# MSS_CTRL_MSS_CTRL_50D00000h register map
Vendor: Texas Instruments
Registers are 32-bit, read-only, reset values left out (the file's numbers can be read two ways) unless marked. A register's access mark holds for its fields unless they carry their own. Offsets are as the file gives them; [hi:lo] are bit positions; {n}, {i} and the like mark numbered series.

## MSS_CTRL (part 2 of 10)
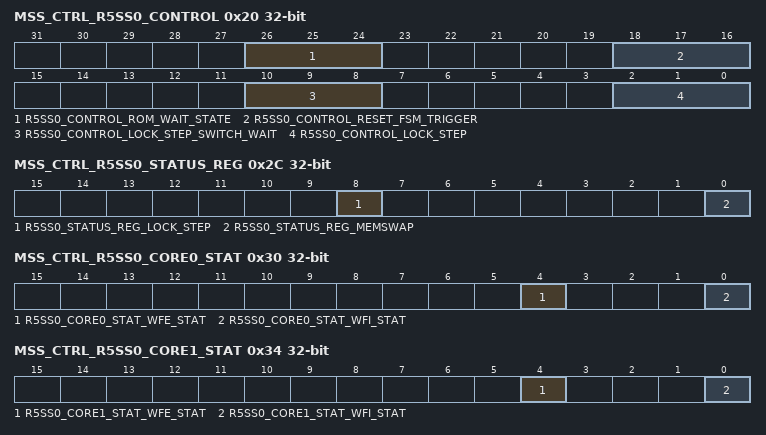
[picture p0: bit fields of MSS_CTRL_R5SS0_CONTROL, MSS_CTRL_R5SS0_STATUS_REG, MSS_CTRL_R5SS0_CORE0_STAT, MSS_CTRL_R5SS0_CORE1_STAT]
0x20 MSS_CTRL_R5SS0_CONTROL rw — This register is used to configure R5SS0 in Lock step or Dual core mode. The mode change can be affected only once in a SOC power cycle.
  [26:24] R5SS0_CONTROL_ROM_WAIT_STATE — Writing 3'b111 enables a single cycle wait state with respect to CR5A_clk for rom access.This needs to be set when R5 clock is at 400MHZ and Interconnect-clk is at 200MHZ. [because it is a timing issue in this scenario]
  [18:16] R5SS0_CONTROL_RESET_FSM_TRIGGER — Write pulse bit field:Writing 3'b111 will trigger the reset FSM. Reset FSM ensures reset to R5SS and inturn ensures the latching of lock_step and also mem_swap bit
  [10:8] R5SS0_CONTROL_LOCK_STEP_SWITCH_WAIT — Writing 3'b111 ensures switch happens only after R5SS reset. Orelse it will be a immediate switch.
  [2:0] R5SS0_CONTROL_LOCK_STEP — Writing 3'b000 ensures R5 to be in Dual-Core mode. Note: The change happens after the R5SS reset assertion if corresponding R5SS_CONTROL_LOCK_STEP_SWITCH_WAIT is set. Or else the switiching to Dual-core happens on the fly.
0x24 MSS_CTRL_R5SS0_CORE0_HALT rw — This register is used to Halt or Unhalt R5SS0 Core 0
  [2:0] R5SS0_COREA_HALT_HALT — Writing 3'b000 will unhalt CR5A. This register should be written only once.
0x28 MSS_CTRL_R5SS0_CORE1_HALT rw — This register is used to Halt or Unhalt R5SS0 Core 1
  [2:0] R5SS0_COREB_HALT_HALT — Writing 3'b000 will unhalt for CR5B. This register should be written only once.
0x2C MSS_CTRL_R5SS0_STATUS_REG — This register shows whether R5SS0 is in Lock step or Dual core mode.
  [8] R5SS0_STATUS_REG_LOCK_STEP — Reading1:confirms R5SS is in lockstep mode. Reading0:confirms R5SS is in Dual-core mode.
  [0] R5SS0_STATUS_REG_MEMSWAP — Reading1:confirms ROM is Eclipsed from with RAM for R5.
0x30 MSS_CTRL_R5SS0_CORE0_STAT — This register shows the WFI WFE status of R5SS0 Core 0
  [4] R5SS0_CORE0_STAT_WFE_STAT — WFE Status
  [0] R5SS0_CORE0_STAT_WFI_STAT — WFI Status
0x34 MSS_CTRL_R5SS0_CORE1_STAT — This register shows the WFI WFE status of R5SS0 Core 1
  [4] R5SS0_CORE1_STAT_WFE_STAT — WFE Status
  [0] R5SS0_CORE1_STAT_WFI_STAT — WFI Status
0x38 MSS_CTRL_MSS_STC_CONTROL0 rw — This register is used to override and force WFI from R5SS0 to RCM.
  [2:0] MSS_STC_CONTROL0_CR5_WFI_OVERIDE — Writing 3'b111 will force the wfi signals of R5SS to 1
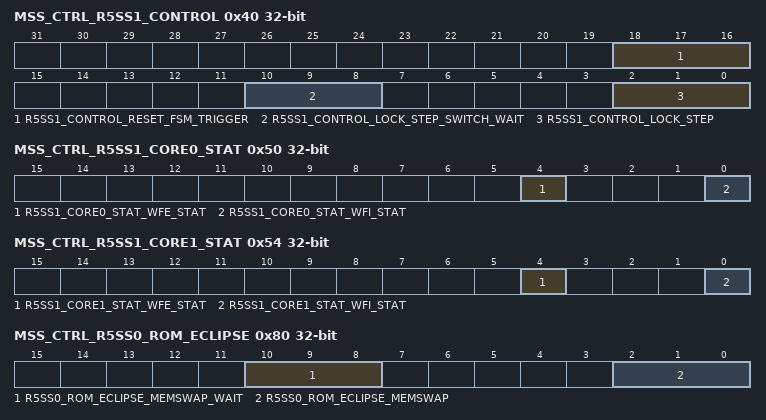
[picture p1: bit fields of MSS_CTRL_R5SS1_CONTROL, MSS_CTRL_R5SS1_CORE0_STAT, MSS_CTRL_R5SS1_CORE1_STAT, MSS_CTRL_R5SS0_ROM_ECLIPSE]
0x40 MSS_CTRL_R5SS1_CONTROL rw — This register is used to configure corresponding R5SS in Lock step or Dual core mode. The mode change can be affected only once in a SOC power cycle.
  [18:16] R5SS1_CONTROL_RESET_FSM_TRIGGER — Write pulse bit field:Writing 3'b111 will trigger the reset FSM. Reset FSM ensures reset to R5SS and inturn ensures the latching of lock_step and also mem_swap bit
  [10:8] R5SS1_CONTROL_LOCK_STEP_SWITCH_WAIT — Writing 3'b111 ensures switch happens only after R5SS reset. Orelse it will be a immediate switch.
  [2:0] R5SS1_CONTROL_LOCK_STEP — Writing 3'b000 ensures R5 to be in Dual-Core mode. Note: The change happens after the R5SS reset assertion if corresponding R5SS_CONTROL_LOCK_STEP_SWITCH_WAIT is set. Or else the switiching to Dual-core happens on the fly.
0x44 MSS_CTRL_R5SS1_CORE0_HALT rw — This register is used to Halt or Unhalt R5SS1 Core 0
  [2:0] R5SS1_COREA_HALT_HALT — Writing 3'b000 will unhalt CR5A. This register should be written only once.
0x48 MSS_CTRL_R5SS1_CORE1_HALT rw — This register is used to Halt or Unhalt R5SS1 Core 1
  [2:0] R5SS1_COREB_HALT_HALT — Writing 3'b000 will unhalt for CR5B. This register should be written only once.
0x4C MSS_CTRL_R5SS1_STATUS_REG — This register shows whether R5SS1 is in Lock step or Dual core mode.
  [8] R5SS1_STATUS_REG_LOCK_STEP — Reading1:confirms R5SS is in lockstep mode. Reading0:confirms R5SS is in Dual-core mode.
0x50 MSS_CTRL_R5SS1_CORE0_STAT — This register shows the WFI WFE status of R5SS1 Core 0
  [4] R5SS1_CORE0_STAT_WFE_STAT — WFE Status
  [0] R5SS1_CORE0_STAT_WFI_STAT — WFI Status
0x54 MSS_CTRL_R5SS1_CORE1_STAT — This register shows the WFI WFE status of R5SS1 Core 1
  [4] R5SS1_CORE1_STAT_WFE_STAT — WFE Status
  [0] R5SS1_CORE1_STAT_WFI_STAT — WFI Status
0x58 MSS_CTRL_MSS_STC_CONTROL1 rw — This register is used to override and force WFI from R5SS1 to RCM.
  [2:0] MSS_STC_CONTROL1_CR5_WFI_OVERIDE — Writing 3'b111 will force the wfi signals of R5SS to 1
0x80 MSS_CTRL_R5SS0_ROM_ECLIPSE rw — R5_ROM_ECLIPSE.
  [10:8] R5SS0_ROM_ECLIPSE_MEMSWAP_WAIT — Writing 3'b111 ensures ROM-Eclipsing happens only after R5SS reset. Or else it will be a immediate change.
  [2:0] R5SS0_ROM_ECLIPSE_MEMSWAP — Writing 3'b111 ensures eclipsing of CR5A_ROM immediately if memswap_wait is not set. If memswap_wait is set then ROM is eclipsed after R5SS reset assertion.
{0x100+4i} MSS_CTRL_MSS_BOOT_INFO_REG{i} rw (i=0..7) — MSS_BOOT_INFO_REG{i}.
  [31:0] MSS_BOOT_INFO_REG{i}_CONFIG — Reserved Register for Software use**Note: Bit is getting reseted only on PORz
0x200 MSS_CTRL_MSS_ATCM0_MEM_INIT rw — This register is used to initialise the data and ECC of ATCM memory of R5SS0 .
  [0] MSS_ATCM0_MEM_INIT_MEM_INIT — Write_pulse bit field:Writing 1'b1 will start initializing the ATCM banks of CR5A/B. Value in each row is initialized to 0x0C_0000_0000
0x204 MSS_CTRL_MSS_ATCM0_MEM_INIT_DONE rw — This register is used to indicate the ATCM memory initialization completion for R5SS0.
  [0] MSS_ATCM0_MEM_INIT_DONE_MEM_INIT_DONE — This field will be high once initialization of ATCM banks is finished. Writing '1' would clear the bit.
0x208 MSS_CTRL_MSS_ATCM0_MEM_INIT_STATUS — This register is used to indicate the status of ongoing memory initialization for ATCM memory of R5SS0.
  [0] MSS_ATCM0_MEM_INIT_STATUS_MEM_STATUS — 1'b0: No initialization is happening for ATCM banks of CR5A/B1'b1: Initialization is in progress for ATCM banks of CR5A/B
0x210 MSS_CTRL_MSS_BTCM0_MEM_INIT rw — This register is used to initialise the data and ECC of BTCM memory of R5SS0 .
  [0] MSS_BTCM0_MEM_INIT_MEM_INIT — Write_pulse bit field:Writing 1'b1 will start initializing the B0/1TCM banks of CR5A/B
0x214 MSS_CTRL_MSS_BTCM0_MEM_INIT_DONE rw — This register is used to indicate the BTCM memory initialization completion for R5SS0.
  [0] MSS_BTCM0_MEM_INIT_DONE_MEM_INIT_DONE — This field will be high once initialization of B0/1TCM banks is finished. Writing '1' would clear the bit.
0x218 MSS_CTRL_MSS_BTCM0_MEM_INIT_STATUS — This register is used to indicate the status of ongoing memory initialization for BTCM memory of R5SS0.
  [0] MSS_BTCM0_MEM_INIT_STATUS_MEM_STATUS — 1'b0: No initialization is happening for B0/1TCM banks of CR5A/B1'b1: Initialization is in progress for B0/1TCM banks of CR5A/B
0x220 MSS_CTRL_MSS_ATCM1_MEM_INIT rw — This register is used to initialise the data and ECC of ATCM memory of R5SS1.
  [0] MSS_ATCM1_MEM_INIT_MEM_INIT — Write_pulse bit field:Writing 1'b1 will start initializing the ATCM banks of CR5A/B. Value in each row is initialized to 0x0C_0000_0000
0x224 MSS_CTRL_MSS_ATCM1_MEM_INIT_DONE rw — This register is used to indicate the ATCM memory initialization completion for R5SS1.
  [0] MSS_ATCM1_MEM_INIT_DONE_MEM_INIT_DONE — This field will be high once initialization of ATCM banks is finished. Writing '1' would clear the bit.
0x228 MSS_CTRL_MSS_ATCM1_MEM_INIT_STATUS — This register is used to indicate the status of ongoing memory initialization for ATCM memory of R5SS1.
  [0] MSS_ATCM1_MEM_INIT_STATUS_MEM_STATUS — 1'b0: No initialization is happening for ATCM banks of CR5A/B1'b1: Initialization is in progress for ATCM banks of CR5A/B
0x230 MSS_CTRL_MSS_BTCM1_MEM_INIT rw — This register is used to initialise the data and ECC of BTCM memory of R5SS1.
  [0] MSS_BTCM1_MEM_INIT_MEM_INIT — Write_pulse bit field:Writing 1'b1 will start initializing the B0/1TCM banks of CR5A/B
0x234 MSS_CTRL_MSS_BTCM1_MEM_INIT_DONE rw — This register is used to indicate the BTCM memory initialization completion for R5SS1.
  [0] MSS_BTCM1_MEM_INIT_DONE_MEM_INIT_DONE — This field will be high once initialization of B0/1TCM banks is finished. Writing '1' would clear the bit.
0x238 MSS_CTRL_MSS_BTCM1_MEM_INIT_STATUS — This register is used to indicate the status of ongoing memory initialization for BTCM memory of R5SS1.
  [0] MSS_BTCM1_MEM_INIT_STATUS_MEM_STATUS — 1'b0: No initialization is happening for B0/1TCM banks of CR5A/B1'b1: Initialization is in progress for B0/1TCM banks of CR5A/B
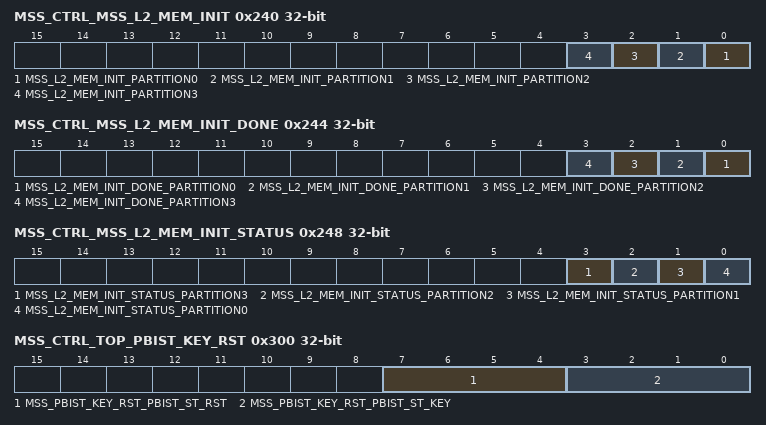
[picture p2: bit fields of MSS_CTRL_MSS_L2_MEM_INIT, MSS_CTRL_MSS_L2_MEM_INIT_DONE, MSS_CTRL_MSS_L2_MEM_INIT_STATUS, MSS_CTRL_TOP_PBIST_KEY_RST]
0x240 MSS_CTRL_MSS_L2_MEM_INIT rw — This register is used to initialise the data and ECC of L2OCRAM.
  [n] MSS_L2_MEM_INIT_PARTITION{n} (n=0..3) — Write_pulse bit field:Writing 1'b1 will start initializing the L2 Bank{n}. Value in each row is initialized to 0x0
0x244 MSS_CTRL_MSS_L2_MEM_INIT_DONE rw — This register is used to indicate the L2OCRAM memory initialization completion .
  [n] MSS_L2_MEM_INIT_DONE_PARTITION{n} (n=0..3) — This field will be high once intialization of L2 bank{n} is finished. Writing '1' would clear the bit
0x248 MSS_CTRL_MSS_L2_MEM_INIT_STATUS — This register is used to indicate the status of ongoing memory initialization for L2OCRAM.
  [3] MSS_L2_MEM_INIT_STATUS_PARTITION3 — 1'b0: No initialization is happening for L2 bank31'b1: Initialization is in progress for L2 bank3
  [2] MSS_L2_MEM_INIT_STATUS_PARTITION2 — 1'b0: No initialization is happening for L2 bank2 1'b1: Initialization is in progress for L2 bank2
  [1] MSS_L2_MEM_INIT_STATUS_PARTITION1 — 1'b0: No initialization is happening for L2 bank11'b1: Initialization is in progress for L2 bank1
  [0] MSS_L2_MEM_INIT_STATUS_PARTITION0 — 1'b0: No initialization is happening for L2 bank0 1'b1: Initialization is in progress for L2 bank0
0x250 MSS_CTRL_MSS_MAILBOX_MEM_INIT rw — This register is used to initialise the data and ECC of MBOX_SRAM.
  [0] MSS_MAILBOX_MEM_INIT_MEM0_INIT — Write_pulse bit field:Writing 1'b1 will start initializing the MSS_MBOX. Value in each row is initialized to 0x0
0x254 MSS_CTRL_MSS_MAILBOX_MEM_INIT_DONE rw — This register is used to indicate the MBOX_SRAM memory initialization completion .
  [0] MSS_MAILBOX_MEM_INIT_DONE_MEM0_DONE — This field will be high once intialization of MSS_MBOX is finished. Writing '1' would clear the bit
0x258 MSS_CTRL_MSS_MAILBOX_MEM_INIT_STATUS — This register is used to indicate the status of ongoing memory initialization for MBOX_SRAM.
  [0] MSS_MAILBOX_MEM_INIT_STATUS_MEM0_STATUS — 1'b0: No initialization is happening for MSS_MBOX 1'b1: Initialization is in progress for MSS_MBOX
0x260 MSS_CTRL_MSS_TPCC_MEMINIT_START rw — This register is used to initialise the data and ECC of EDMA_TPCC RAM.
  [0] MSS_TPCC_MEMINIT_START_TPCC_A_MEMINIT_START — Write_pulse bit field:Writing 1'b1 will start initializing the MSS_TPCCA
0x264 MSS_CTRL_MSS_TPCC_MEMINIT_DONE rw — This register is used to indicate the EDMA_TPCC memory initialization completion .
  [0] MSS_TPCC_MEMINIT_DONE_TPCC_A_MEMINIT_DONE — This field will be high once intialization of MSS_TPCCA is finished. Writing '1' would clear the bit
0x268 MSS_CTRL_MSS_TPCC_MEMINIT_STATUS — This register is used to indicate the status of ongoing memory initialization for EDMA_TPCC RAM.
  [0] MSS_TPCC_MEMINIT_STATUS_TPCC_A_MEMINIT_STATUS — 1'b0: No initialization is happening for MSS_TPCCA1'b1: Initialization is in progress for MSS_TPCCB
0x300 MSS_CTRL_TOP_PBIST_KEY_RST rw — This register is used to enable Top Pbist module.
  [7:4] MSS_PBIST_KEY_RST_PBIST_ST_RST — MSS PBIST controller will be brought out of reset when value is 0xA
  [3:0] MSS_PBIST_KEY_RST_PBIST_ST_KEY — Top PBIST Selftest Key. Valid value is 0x5
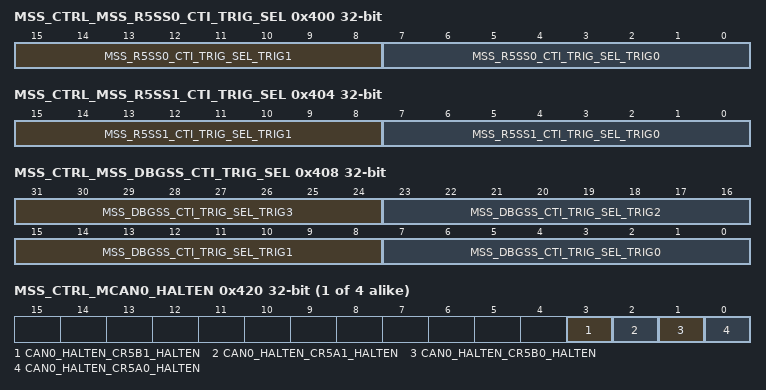
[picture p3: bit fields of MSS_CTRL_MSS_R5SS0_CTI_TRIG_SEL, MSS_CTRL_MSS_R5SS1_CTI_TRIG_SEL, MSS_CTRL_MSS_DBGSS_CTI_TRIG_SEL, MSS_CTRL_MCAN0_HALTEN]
0x400 MSS_CTRL_MSS_R5SS0_CTI_TRIG_SEL rw — This register is used to select the two CTI trigger sources for R5SS[x]
  [15:8] MSS_R5SS0_CTI_TRIG_SEL_TRIG1 — Used for selecting the trigger source for 1st trigger of MSS_R5SS
  [7:0] MSS_R5SS0_CTI_TRIG_SEL_TRIG0 — Used for selecting the trigger source for 0th trigger of MSS_R5SS
0x404 MSS_CTRL_MSS_R5SS1_CTI_TRIG_SEL rw — This register is used to select the two CTI trigger sources for R5SS[x]
  [15:8] MSS_R5SS1_CTI_TRIG_SEL_TRIG1 — Used for selecting the trigger source for 1st trigger of MSS_R5SS
  [7:0] MSS_R5SS1_CTI_TRIG_SEL_TRIG0 — Used for selecting the trigger source for 0th trigger of MSS_R5SS
0x408 MSS_CTRL_MSS_DBGSS_CTI_TRIG_SEL rw — This register is used to select thefour CTI trigger sources for DEBUGSS.
  [31:24] MSS_DBGSS_CTI_TRIG_SEL_TRIG3 — Used for selecting the trigger source for 3rd trigger of ONE_MCU_CTI
  [23:16] MSS_DBGSS_CTI_TRIG_SEL_TRIG2 — Used for selecting the trigger source for 2nd trigger of ONE_MCU_CTI
  [15:8] MSS_DBGSS_CTI_TRIG_SEL_TRIG1 — Used for selecting the trigger source for 1st trigger of ONE_MCU_CTI
  [7:0] MSS_DBGSS_CTI_TRIG_SEL_TRIG0 — Used for selecting the trigger source for 0th trigger of ONE_MCU_CTI
{0x420+4i} MSS_CTRL_MCAN{i}_HALTEN rw (i=0..3) — This register selects which R5 CPU when debug halted shall halt MCAN[x] Peripheral.
  [3] CAN{i}_HALTEN_CR5B1_HALTEN — 1'b0: IP Halt disabled with corresponding CPU halt1'b1: IP Halt enabled with corresponding CPU halt
  [2] CAN{i}_HALTEN_CR5A1_HALTEN — 1'b0: IP Halt disabled with corresponding CPU halt1'b1: IP Halt enabled with corresponding CPU halt
  [1] CAN{i}_HALTEN_CR5B0_HALTEN — 1'b0: IP Halt disabled with corresponding CPU halt1'b1: IP Halt enabled with corresponding CPU halt
  [0] CAN{i}_HALTEN_CR5A0_HALTEN — 1'b0: IP Halt disabled with corresponding CPU halt1'b1: IP Halt enabled with corresponding CPU halt
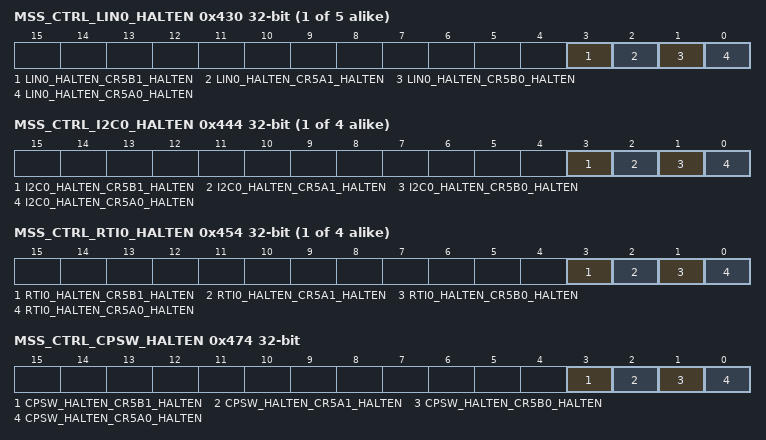
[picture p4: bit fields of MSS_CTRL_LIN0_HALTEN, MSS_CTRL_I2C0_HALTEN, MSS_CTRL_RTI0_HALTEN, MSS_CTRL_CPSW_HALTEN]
{0x430+4i} MSS_CTRL_LIN{i}_HALTEN rw (i=0..4) — This register selects which R5 CPU when debug halted shall halt LIN[x] Peripheral.
  [3] LIN{i}_HALTEN_CR5B1_HALTEN — 1'b0: IP Halt disabled with corresponding CPU halt1'b1: IP Halt enabled with corresponding CPU halt
  [2] LIN{i}_HALTEN_CR5A1_HALTEN — 1'b0: IP Halt disabled with corresponding CPU halt1'b1: IP Halt enabled with corresponding CPU halt
  [1] LIN{i}_HALTEN_CR5B0_HALTEN — 1'b0: IP Halt disabled with corresponding CPU halt1'b1: IP Halt enabled with corresponding CPU halt
  [0] LIN{i}_HALTEN_CR5A0_HALTEN — 1'b0: IP Halt disabled with corresponding CPU halt1'b1: IP Halt enabled with corresponding CPU halt
{0x444+4i} MSS_CTRL_I2C{i}_HALTEN rw (i=0..3) — This register selects which R5 CPU when debug halted shall halt I2C[x] Peripheral.
  [3] I2C{i}_HALTEN_CR5B1_HALTEN — 1'b0: IP Halt disabled with corresponding CPU halt1'b1: IP Halt enabled with corresponding CPU halt
  [2] I2C{i}_HALTEN_CR5A1_HALTEN — 1'b0: IP Halt disabled with corresponding CPU halt1'b1: IP Halt enabled with corresponding CPU halt
  [1] I2C{i}_HALTEN_CR5B0_HALTEN — 1'b0: IP Halt disabled with corresponding CPU halt1'b1: IP Halt enabled with corresponding CPU halt
  [0] I2C{i}_HALTEN_CR5A0_HALTEN — 1'b0: IP Halt disabled with corresponding CPU halt1'b1: IP Halt enabled with corresponding CPU halt
{0x454+4i} MSS_CTRL_RTI{i}_HALTEN rw (i=0..3) — This register selects which R5 CPU when debug halted shall halt RTI[x] Peripheral.
  [3] RTI{i}_HALTEN_CR5B1_HALTEN — 1'b0: IP Halt disabled with corresponding CPU halt1'b1: IP Halt enabled with corresponding CPU halt
  [2] RTI{i}_HALTEN_CR5A1_HALTEN — 1'b0: IP Halt disabled with corresponding CPU halt1'b1: IP Halt enabled with corresponding CPU halt
  [1] RTI{i}_HALTEN_CR5B0_HALTEN — 1'b0: IP Halt disabled with corresponding CPU halt1'b1: IP Halt enabled with corresponding CPU halt
  [0] RTI{i}_HALTEN_CR5A0_HALTEN — 1'b0: IP Halt disabled with corresponding CPU halt1'b1: IP Halt enabled with corresponding CPU halt
0x474 MSS_CTRL_CPSW_HALTEN rw — This register selects which R5 CPU when debug halted shall halt CPSW Peripheral.
  [3] CPSW_HALTEN_CR5B1_HALTEN — 1'b0: IP Halt disabled with corresponding CPU halt1'b1: IP Halt enabled with corresponding CPU halt
  [2] CPSW_HALTEN_CR5A1_HALTEN — 1'b0: IP Halt disabled with corresponding CPU halt1'b1: IP Halt enabled with corresponding CPU halt
  [1] CPSW_HALTEN_CR5B0_HALTEN — 1'b0: IP Halt disabled with corresponding CPU halt1'b1: IP Halt enabled with corresponding CPU halt
  [0] CPSW_HALTEN_CR5A0_HALTEN — 1'b0: IP Halt disabled with corresponding CPU halt1'b1: IP Halt enabled with corresponding CPU halt
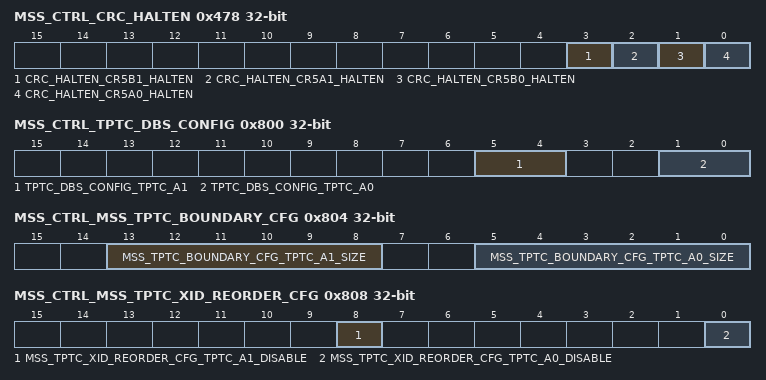
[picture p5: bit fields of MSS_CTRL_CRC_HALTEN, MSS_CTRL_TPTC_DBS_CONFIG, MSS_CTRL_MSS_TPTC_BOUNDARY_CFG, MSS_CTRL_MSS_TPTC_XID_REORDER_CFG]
0x478 MSS_CTRL_CRC_HALTEN rw — This register selects which R5 CPU when debug halted shall halt MCRC Peripheral.
  [3] CRC_HALTEN_CR5B1_HALTEN — 1'b0: IP Halt disabled with corresponding CPU halt1'b1: IP Halt enabled with corresponding CPU halt
  [2] CRC_HALTEN_CR5A1_HALTEN — 1'b0: IP Halt disabled with corresponding CPU halt1'b1: IP Halt enabled with corresponding CPU halt
  [1] CRC_HALTEN_CR5B0_HALTEN — 1'b0: IP Halt disabled with corresponding CPU halt1'b1: IP Halt enabled with corresponding CPU halt
  [0] CRC_HALTEN_CR5A0_HALTEN — 1'b0: IP Halt disabled with corresponding CPU halt1'b1: IP Halt enabled with corresponding CPU halt
0x800 MSS_CTRL_TPTC_DBS_CONFIG rw — This register controls the default burst size of EDMA TPTC.
  [5:4] TPTC_DBS_CONFIG_TPTC_A1 — DBS [default burst size] tieoff value for TPTC A1. DBS tieoff defines optimally sized cmd.Both the read and write controller will always issue commands that are less than or equal to the DBS tieoff value. This will typically be on the order of 4 or 8 dataphases worth of data. DBS must always be tied off to no larger than half of the Channel FIFO size. Set DBS to -2'b00 = 16 byte 2'b01 = 32 byte 2'b10 = 64 byte 2'b11 = 128 byte
  [1:0] TPTC_DBS_CONFIG_TPTC_A0 — DBS [default burst size] tieoff value for TPTC A0. DBS tieoff defines optimally sized cmd.Both the read and write controller will always issue commands that are less than or equal to the DBS tieoff value. This will typically be on the order of 4 or 8 dataphases worth of data. DBS must always be tied off to no larger than half of the Channel FIFO size. Set DBS to -2'b00 = 16 byte 2'b01 = 32 byte 2'b10 = 64 byte 2'b11 = 128 byte
0x804 MSS_CTRL_MSS_TPTC_BOUNDARY_CFG rw — The register is used to control TPTC boundary configuration.
  [13:8] MSS_TPTC_BOUNDARY_CFG_TPTC_A1_SIZE — 6 bit signal used for deciding the boundary crossing size for CID-RID-SID reordering of MSS_TPTC_A1Example: Writing 6'd19 decidies boundary to be 2^19 i.e. 512 KB
  [5:0] MSS_TPTC_BOUNDARY_CFG_TPTC_A0_SIZE — 6 bit signal used for deciding the boundary crossing size for CID-RID-SID reordering of MSS_TPTC_A0Example: Writing 6'd19 decidies boundary to be 2^19 i.e. 512 KB
0x808 MSS_CTRL_MSS_TPTC_XID_REORDER_CFG rw — The register is used to control TPTC XID reorder configuration.
  [8] MSS_TPTC_XID_REORDER_CFG_TPTC_A1_DISABLE — Writing 1'b1 will disable the CID-RID-SID reodering feature for MSS_TPTC_A1
  [0] MSS_TPTC_XID_REORDER_CFG_TPTC_A0_DISABLE — Writing 1'b1 will disable the CID-RID-SID reodering feature for MSS_TPTC_A0
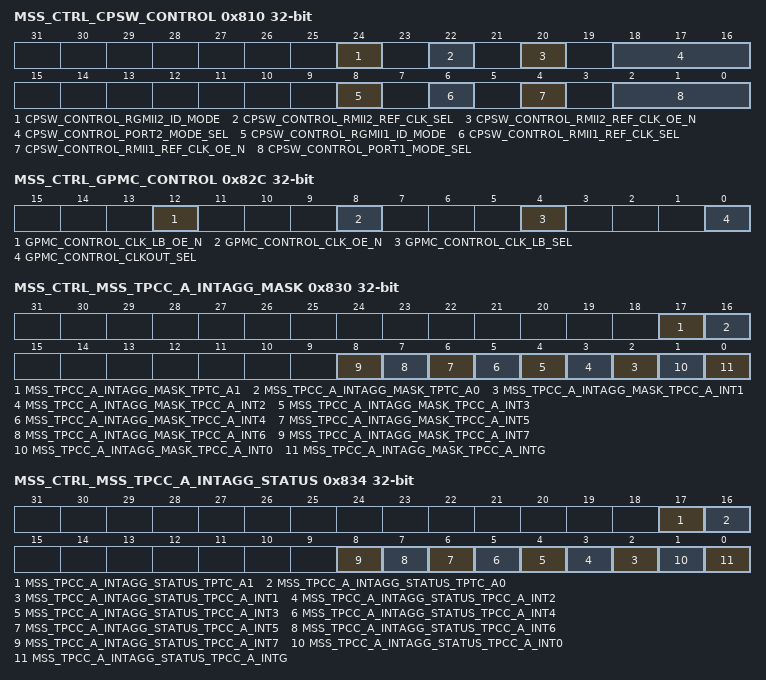
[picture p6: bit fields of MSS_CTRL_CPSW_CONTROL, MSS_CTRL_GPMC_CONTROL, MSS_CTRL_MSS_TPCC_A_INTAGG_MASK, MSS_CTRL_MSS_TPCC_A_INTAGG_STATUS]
0x810 MSS_CTRL_CPSW_CONTROL rw — Ther register is for the CPSW Ethernet modes and additional controls on the.
  [24] CPSW_CONTROL_RGMII2_ID_MODE — Internal delay mode for port 2. Only for TX1'b0 ID mode is disabled1'b1 ID mode is enabled
  [22] CPSW_CONTROL_RMII2_REF_CLK_SEL — To select the rmii_ref_clk loopback mux output either from PAD or from MSS_RCM. Write 1'b0 to get clock will be from IO pad[pad loopback]. Write 1'b1 to get clock from internal loopback.
  [20] CPSW_CONTROL_RMII2_REF_CLK_OE_N — RMII_REF_CLK IO Output enable control1'b0: Output enable1'b1: Output Disable
  [18:16] CPSW_CONTROL_PORT2_MODE_SEL — Port 2 Interface 3'b000 = MII3'b001 = RMII3'b010 = RGMII011 - 111 = Not Supported
  [8] CPSW_CONTROL_RGMII1_ID_MODE — Internal delay mode for port 1. Only for TX1'b0 ID mode is disabled1'b1 ID mode is enabled
  [6] CPSW_CONTROL_RMII1_REF_CLK_SEL — To select the rmii_ref_clk loopback mux output either from PAD or from MSS_RCM. Write 1'b0 to get clock will be from IO pad[pad loopback]. Write 1'b1 to get clock from internal source
  [4] CPSW_CONTROL_RMII1_REF_CLK_OE_N — RMII_REF_CLK IO Output enable control1'b0: Output enable1'b1: Output Disable
  [2:0] CPSW_CONTROL_PORT1_MODE_SEL — Port 1 Interface 3'b000 = MII3'b001 = RMII3'b010 = RGMII011 - 111 = Not Supported
0x818 MSS_CTRL_GLOBAL_CONTROLS rw — Internal Only.
  [0] GLOBAL_CONTROLS_NOGATE — Writing 1'b0 will enable local auto-clock gating [lower power] at IP level with increase in access/functional latency. Following IPs are controlled with this signalICSSM
0x81C MSS_CTRL_PRU_ICSS_PRU0_GPI_SEL rw — Selects Chip input or Control peripheral for ICSSM PRU0 GPI source.
  [29:0] PRU_ICSS_PRU0_GPI_SEL_SEL — GPI or PWMXBAR select for ICSM Port01'b0 GPI1'b1 PWMXBAR
0x820 MSS_CTRL_PRU_ICSS_PRU1_GPI_SEL rw — Selects Chip input or Control peripheral for ICSSM PRU1 GPI source.
  [29:0] PRU_ICSS_PRU1_GPI_SEL_SEL — GPI or PWMXBAR select for ICSM Port01'b0 GPI1'b1 PWMXBAR
0x824 MSS_CTRL_PRU_ICSS_PRU0_GPIO_OUT_CTRL rw — Controls the Output enable of the ICSSM PRU0 GPIO pins.
  [29:0] PRU_ICSS_PRU0_GPIO_OUT_CTRL_OUTDISABLE — GPO output disable for ICSSM Port 0 IO. Disable output for using the pin as input. Each Bit maps to the corresponding bit in the IO1'b0 Output Enable1'b1 Output Disable
0x828 MSS_CTRL_PRU_ICSS_PRU1_GPIO_OUT_CTRL rw — Controls the Output enable of the ICSSM PRU1 GPIO pins.
  [29:0] PRU_ICSS_PRU1_GPIO_OUT_CTRL_OUTDISABLE — GPO output disable for ICSSM Port 1 IO. Disable output for using the pin as input. Each Bit maps to the corresponding bit in the IO1'b0 Output Enable1'b1 Output Disable
0x82C MSS_CTRL_GPMC_CONTROL rw — This register is used to configure the GPMC Clock source and Loop Back clock Source.
  [12] GPMC_CONTROL_CLK_LB_OE_N — GPMC_CLK_LB oe_n1'b1 GPMC_dev_clk is driven to pad1'b0 GPMC_dev_clk is not driven to pad
  [8] GPMC_CONTROL_CLK_OE_N — GPMC_CLKOUT oe_n1'b1 GPMC_dev_clk mux output is driven to pad1'b0 GPMC_dev_clk mux output is not driven to pad
  [4] GPMC_CONTROL_CLK_LB_SEL — GPMC_CLK_LB sel1'b0 GPMC_CLK_LB pad clock1'b1 GPMC_CLK pad clock
  [0] GPMC_CONTROL_CLKOUT_SEL — GPMC_CLKOUT sel1'b0 GPMC_func_clock1'b1 GPMC_dev clock
0x830 MSS_CTRL_MSS_TPCC_A_INTAGG_MASK rw — This register Masks selected interrupt soures from the Aggregated TPCC0 interrupt.
  [17] MSS_TPCC_A_INTAGG_MASK_TPTC_A1 — Mask Interrupt from TPTC A1 to aggregated Interrupt MSS_TPCC_A_INTAGG1'b1 : Interrupt is Masked1'b0 : Interrupt is Unmasked
  [16] MSS_TPCC_A_INTAGG_MASK_TPTC_A0 — Mask Interrupt from TPTC A0 to aggregated Interrupt MSS_TPCC_A_INTAGG1'b1 : Interrupt is Masked1'b0 : Interrupt is Unmasked
  [n+1] MSS_TPCC_A_INTAGG_MASK_TPCC_A_INT{n} (n=1..7) — Mask Interrupt from MSS_TPCC_A to aggregated Interrupt MSS_TPCC_A_INTAGG1'b1 : Interrupt is Masked1'b0 : Interrupt is Unmasked
  [1] MSS_TPCC_A_INTAGG_MASK_TPCC_A_INT0 — Mask Interrupt from TPCC A to aggregated Interrupt MSS_TPCC_A_INTAGG1'b1 : Interrupt is Masked1'b0 : Interrupt is Unmasked
  [0] MSS_TPCC_A_INTAGG_MASK_TPCC_A_INTG — Mask Interrupt from MSS_TPCC_A to aggregated Interrupt MSS_TPCC_A_INTAGG1'b1 : Interrupt is Masked1'b0 : Interrupt is Unmasked
0x834 MSS_CTRL_MSS_TPCC_A_INTAGG_STATUS rw — This register shows the Status of Unmasked Interrupts from TPCC0.
  [17] MSS_TPCC_A_INTAGG_STATUS_TPTC_A1 — Status of Interrupt from TPTC A1. Set only if Interupt is unmasked in MSS_TPCC_A_INTAGG_MASKWrie 0x1 to clear this interrupt.
  [16] MSS_TPCC_A_INTAGG_STATUS_TPTC_A0 — Status of Interrupt from TPTC A0. Set only if Interupt is unmasked in MSS_TPCC_A_INTAGG_MASKWrie 0x1 to clear this interrupt.
  [n+1] MSS_TPCC_A_INTAGG_STATUS_TPCC_A_INT{n} (n=1..7) — Status of Interrupt from MSS_TPCC_A. Set only if Interupt is unmasked in MSS_TPCC_A_INTAGG_MASKWrie 0x1 to clear this interrupt.
  [1] MSS_TPCC_A_INTAGG_STATUS_TPCC_A_INT0 — Status of Interrupt from TPCC A Set only if Interupt is unmasked in MSS_TPCC_A_INTAGG_MASKWrie 0x1 to clear this interrupt.
  [0] MSS_TPCC_A_INTAGG_STATUS_TPCC_A_INTG — Status of Interrupt from MSS_TPCC_A. Set only if Interupt is unmasked in MSS_TPCC_A_INTAGG_MASKWrie 0x1 to clear this interrupt.
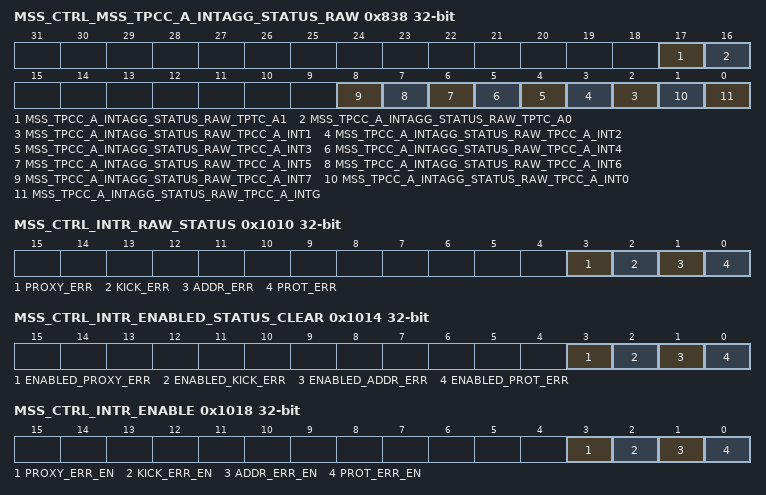
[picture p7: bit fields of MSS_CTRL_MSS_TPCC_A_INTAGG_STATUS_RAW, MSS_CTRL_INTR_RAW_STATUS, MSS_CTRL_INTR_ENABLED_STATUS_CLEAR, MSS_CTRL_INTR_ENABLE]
0x838 MSS_CTRL_MSS_TPCC_A_INTAGG_STATUS_RAW rw — This register shows the Status of all Interrupts from TPCC0.
  [17] MSS_TPCC_A_INTAGG_STATUS_RAW_TPTC_A1 — Raw Status of Interrupt from TPTC A1. Set irrespective if the Interupt is masked or unmasked in MSS_TPCC_A_INTAGG_MASK
  [16] MSS_TPCC_A_INTAGG_STATUS_RAW_TPTC_A0 — Raw Status of Interrupt from TPTC A0. Set irrespective if the Interupt is masked or unmasked in MSS_TPCC_A_INTAGG_MASK
  [n+1] MSS_TPCC_A_INTAGG_STATUS_RAW_TPCC_A_INT{n} (n=1..7) — Raw Status of Interrupt from MSS_TPCC_A. Set irrespective if the Interupt is masked or unmasked in MSS_TPCC_C_INTAGG_MASK
  [1] MSS_TPCC_A_INTAGG_STATUS_RAW_TPCC_A_INT0 — Raw Status of Interrupt from TPCC A. Set irrespective if the Interupt is masked or unmasked in MSS_TPCC_A_INTAGG_MASK
  [0] MSS_TPCC_A_INTAGG_STATUS_RAW_TPCC_A_INTG — Raw Status of Interrupt from MSS_TPCC_A. Set irrespective if the Interupt is masked or unmasked in MSS_TPCC_C_INTAGG_MASK
0x1008 MSS_CTRL_LOCK0_KICK0 rw — - KICK0 component.
  [31:0] LOCK0_KICK0 — - KICK0 component
0x100C MSS_CTRL_LOCK0_KICK1 rw — - KICK1 component.
  [31:0] LOCK0_KICK1 — - KICK1 component
0x1010 MSS_CTRL_INTR_RAW_STATUS access not given — Interrupt Raw Status/Set Register.
  [3] PROXY_ERR — Proxy0 access violation error. Raw status is read. Write a 1 to set the status. Writing a 0 has no effect. (access R/W1TS)
  [2] KICK_ERR — Kick access violation error. Raw status is read. Write a 1 to set the status. Writing a 0 has no effect. (access R/W1TS)
  [1] ADDR_ERR — Addressing violation error. Raw status is read. Write a 1 to set the status. Writing a 0 has no effect. (access R/W1TS)
  [0] PROT_ERR — Protection violation error. Raw status is read. Write a 1 to set the status. Writing a 0 has no effect. (access R/W1TS)
0x1014 MSS_CTRL_INTR_ENABLED_STATUS_CLEAR access not given — Interrupt Enabled Status/Clear register.
  [3] ENABLED_PROXY_ERR — Proxy0 access violation error. Enabled status is read. Write a 1 to clear the status. Writing a 0 has no effect. (access R/W1TC)
  [2] ENABLED_KICK_ERR — Kick access violation error. Enabled status is read. Write a 1 to clear the status. Writing a 0 has no effect. (access R/W1TC)
  [1] ENABLED_ADDR_ERR — Addressing violation error. Enabled status is read. Write a 1 to clear the status. Writing a 0 has no effect. (access R/W1TC)
  [0] ENABLED_PROT_ERR — Protection violation error. Enabled status is read. Write a 1 to clear the status. Writing a 0 has no effect. (access R/W1TC)
0x1018 MSS_CTRL_INTR_ENABLE access not given — Interrupt Enable register.
  [3] PROXY_ERR_EN — Proxy0 access violation error enable. Write a 1 to set the enable. Writing a 0 has no effect. (access R/W1TS)
  [2] KICK_ERR_EN — Kick access violation error enable. Write a 1 to set the enable. Writing a 0 has no effect. (access R/W1TS)
  [1] ADDR_ERR_EN — Addressing violation error enable. Write a 1 to set the enable. Writing a 0 has no effect. (access R/W1TS)
  [0] PROT_ERR_EN — Protection violation error enable. Write a 1 to set the enable. Writing a 0 has no effect. (access R/W1TS)
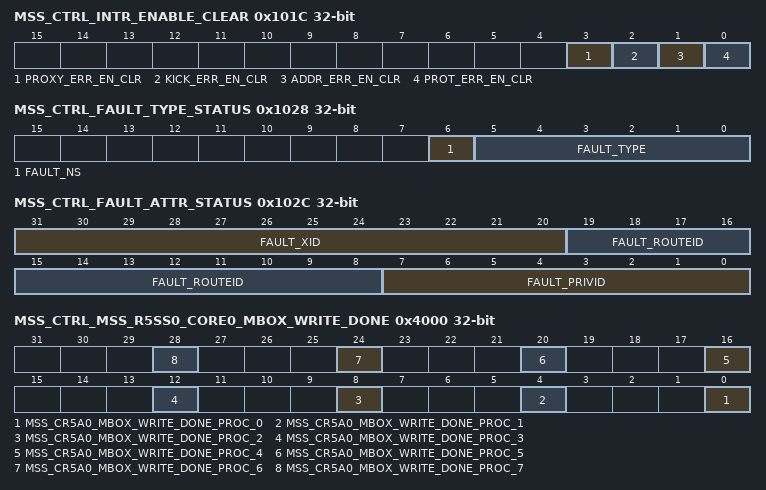
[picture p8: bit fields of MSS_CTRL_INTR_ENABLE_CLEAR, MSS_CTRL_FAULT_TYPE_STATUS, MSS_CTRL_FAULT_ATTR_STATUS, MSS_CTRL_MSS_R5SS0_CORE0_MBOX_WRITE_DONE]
0x101C MSS_CTRL_INTR_ENABLE_CLEAR access not given — Interrupt Enable Clear register.
  [3] PROXY_ERR_EN_CLR — Proxy0 access violation error enable clear. Write a 1 to clear the enable. Writing a 0 has no effect. (access R/W1TC)
  [2] KICK_ERR_EN_CLR — Kick access violation error enable clear. Write a 1 to clear the enable. Writing a 0 has no effect. (access R/W1TC)
  [1] ADDR_ERR_EN_CLR — Addressing violation error enable clear. Write a 1 to clear the enable. Writing a 0 has no effect. (access R/W1TC)
  [0] PROT_ERR_EN_CLR — Protection violation error enable clear. Write a 1 to clear the enable. Writing a 0 has no effect. (access R/W1TC)
0x1020 MSS_CTRL_EOI rw — EOI register.
  [7:0] EOI_VECTOR — EOI vector value. Write this with interrupt distribution value in the chip.
0x1024 MSS_CTRL_FAULT_ADDRESS — Fault Address register.
  [31:0] FAULT_ADDR — Fault Address.
0x1028 MSS_CTRL_FAULT_TYPE_STATUS — Fault Type Status register.
  [6] FAULT_NS — Non-secure access.
  [5:0] FAULT_TYPE — Fault Type 10_0000 = Supervisor read fault - priv = 1 dir = 1 dtype != 1 01_0000 = Supervisor write fault - priv = 1 dir = 0 00_1000 = Supervisor execute fault - priv = 1 dir = 1 dtype = 1 00_0100 = User read fault - priv = 0 dir = 1 dtype = 1 00_0010 = User write fault - priv = 0 dir = 0 00_0001 = User execute fault - priv = 0 dir = 1 dtype = 1 00_0000 = No fault
0x102C MSS_CTRL_FAULT_ATTR_STATUS — Fault Attribute Status register.
  [31:20] FAULT_XID — XID.
  [19:8] FAULT_ROUTEID — Route ID.
  [7:0] FAULT_PRIVID — Privilege ID.
0x1030 MSS_CTRL_FAULT_CLEAR wo — Fault Clear register.
  [0] FAULT_CLR — Fault clear. Writing a 1 clears the current fault. Writing a 0 has no effect.
0x4000 MSS_CTRL_MSS_R5SS0_CORE0_MBOX_WRITE_DONE rw — This register is used by R5SS0 Core 0 to generate Mailbox interrupt to Recipent CPU.
  [4n] MSS_CR5A0_MBOX_WRITE_DONE_PROC_{n} (n=0..7) — Write pulse bit field:This register should be written once finishing Writing into the mailbox memory of processor {n}
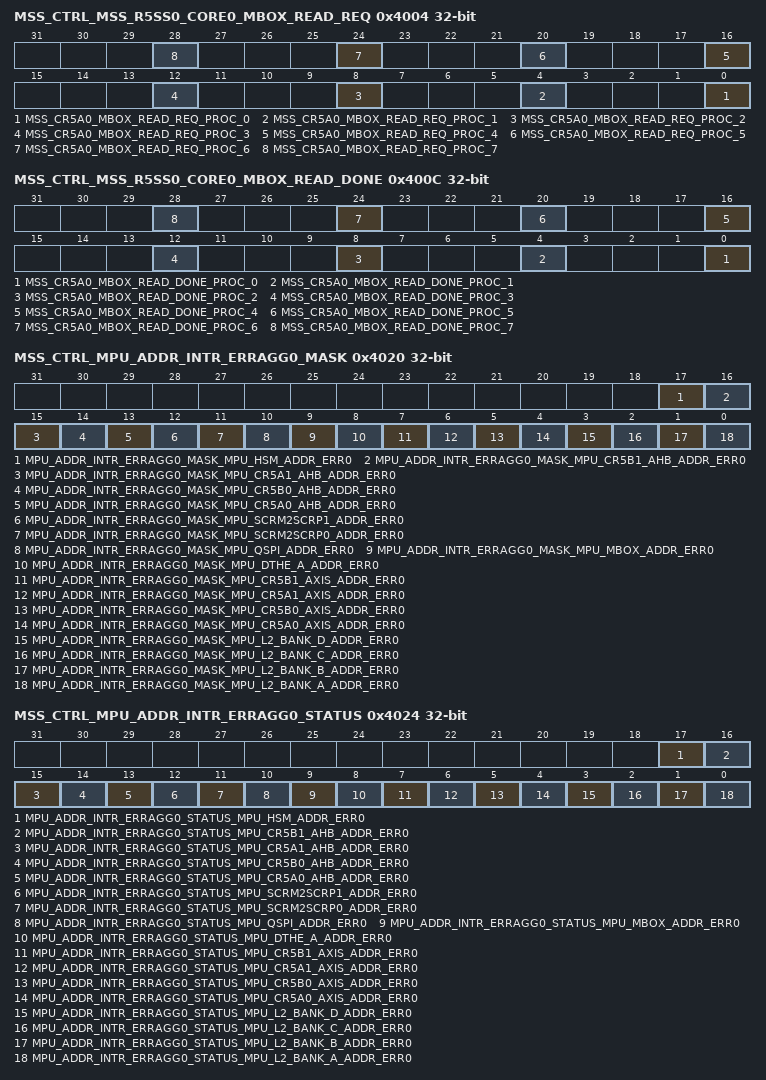
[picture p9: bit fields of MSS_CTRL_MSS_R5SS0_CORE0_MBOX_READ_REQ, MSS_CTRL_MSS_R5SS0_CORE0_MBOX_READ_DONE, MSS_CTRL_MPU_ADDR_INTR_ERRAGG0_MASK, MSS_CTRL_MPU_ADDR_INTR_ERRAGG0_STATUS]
0x4004 MSS_CTRL_MSS_R5SS0_CORE0_MBOX_READ_REQ rw — This register is used by R5SS0 Core 0 to know the Sender of Mailbox Interrupt as well as clear it.
  [4n] MSS_CR5A0_MBOX_READ_REQ_PROC_{n} (n=0..7) — This is request from processor {n} to mss_cr5a. Requesting it to read from mailbox.
0x4008 MSS_CTRL_MSS_R5SS0_CORE0_MBOX_READ_DONE_ACK rw — This register is used by R5SS0 Core 0 to generate Mailbox Read acknowledgement to the Sender CPU.
  [7:0] MSS_CR5A0_MBOX_READ_DONE_ACK_PROC — Write pulse bit field:For bits 0 to7:Wrting1'b1 : Generates pulse interrupt to corresponding proc from MSS_CR5
0x400C MSS_CTRL_MSS_R5SS0_CORE0_MBOX_READ_DONE rw — This register is used by R5SS0 Core 0 to know that the Receiver CPU has read the Mailbox and Acked. It is also used to clear the Read Done Interrupt.
  [4n] MSS_CR5A0_MBOX_READ_DONE_PROC_{n} (n=0..7) — This register should be written once finishing Reading from proc{n}'s mailbox written by CR5A
0x4010 MSS_CTRL_MSS_SW_INT_R5SS0_CORE0 rw — This Register is used to generate a S/W Triggered Interrupt to R5SS0 Core0.
  [0] MSS_SW_INT_R5SS0_CORE0_PULSE — Write_pulse bit field:Writing 1'b1 to each bit will trigger MSS_SW_INT respectively to corresponding R5SS core
0x4020 MSS_CTRL_MPU_ADDR_INTR_ERRAGG0_MASK rw — This register Masks selected interrupt soures from generating MPU Address Error Interrupt to R5SS0 CORE0 .
  [17] MPU_ADDR_INTR_ERRAGG0_MASK_MPU_HSM_ADDR_ERR0 — Mask Error from MPU_ADDR_INTR to aggregated Error MPU_ADDR_INTR_ERRAGG1'b1 : Error is Masked1'b0 : Error is Unmasked
  [16] MPU_ADDR_INTR_ERRAGG0_MASK_MPU_CR5B1_AHB_ADDR_ERR0 — Mask Error from MPU_ADDR_INTR to aggregated Error MPU_ADDR_INTR_ERRAGG1'b1 : Error is Masked1'b0 : Error is Unmasked
  [15] MPU_ADDR_INTR_ERRAGG0_MASK_MPU_CR5A1_AHB_ADDR_ERR0 — Mask Error from MPU_ADDR_INTR to aggregated Error MPU_ADDR_INTR_ERRAGG1'b1 : Error is Masked1'b0 : Error is Unmasked
  [14] MPU_ADDR_INTR_ERRAGG0_MASK_MPU_CR5B0_AHB_ADDR_ERR0 — Mask Error from MPU_ADDR_INTR to aggregated Error MPU_ADDR_INTR_ERRAGG1'b1 : Error is Masked1'b0 : Error is Unmasked
  [13] MPU_ADDR_INTR_ERRAGG0_MASK_MPU_CR5A0_AHB_ADDR_ERR0 — Mask Error from MPU_ADDR_INTR to aggregated Error MPU_ADDR_INTR_ERRAGG1'b1 : Error is Masked1'b0 : Error is Unmasked
  [12] MPU_ADDR_INTR_ERRAGG0_MASK_MPU_SCRM2SCRP1_ADDR_ERR0 — Mask Error from MPU_ADDR_INTR to aggregated Error MPU_ADDR_INTR_ERRAGG1'b1 : Error is Masked1'b0 : Error is Unmasked
  [11] MPU_ADDR_INTR_ERRAGG0_MASK_MPU_SCRM2SCRP0_ADDR_ERR0 — Mask Error from MPU_ADDR_INTR to aggregated Error MPU_ADDR_INTR_ERRAGG1'b1 : Error is Masked1'b0 : Error is Unmasked
  [10] MPU_ADDR_INTR_ERRAGG0_MASK_MPU_QSPI_ADDR_ERR0 — Mask Error from MPU_ADDR_INTR to aggregated Error MPU_ADDR_INTR_ERRAGG1'b1 : Error is Masked1'b0 : Error is Unmasked
  [9] MPU_ADDR_INTR_ERRAGG0_MASK_MPU_MBOX_ADDR_ERR0 — Mask Error from MPU_ADDR_INTR to aggregated Error MPU_ADDR_INTR_ERRAGG1'b1 : Error is Masked1'b0 : Error is Unmasked
  [8] MPU_ADDR_INTR_ERRAGG0_MASK_MPU_DTHE_A_ADDR_ERR0 — Mask Error from MPU_ADDR_INTR to aggregated Error MPU_ADDR_INTR_ERRAGG1'b1 : Error is Masked1'b0 : Error is Unmasked
  [7] MPU_ADDR_INTR_ERRAGG0_MASK_MPU_CR5B1_AXIS_ADDR_ERR0 — Mask Error from MPU_ADDR_INTR to aggregated Error MPU_ADDR_INTR_ERRAGG1'b1 : Error is Masked1'b0 : Error is Unmasked
  [6] MPU_ADDR_INTR_ERRAGG0_MASK_MPU_CR5A1_AXIS_ADDR_ERR0 — Mask Error from MPU_ADDR_INTR to aggregated Error MPU_ADDR_INTR_ERRAGG1'b1 : Error is Masked1'b0 : Error is Unmasked
  [5] MPU_ADDR_INTR_ERRAGG0_MASK_MPU_CR5B0_AXIS_ADDR_ERR0 — Mask Error from MPU_ADDR_INTR to aggregated Error MPU_ADDR_INTR_ERRAGG1'b1 : Error is Masked1'b0 : Error is Unmasked
  [4] MPU_ADDR_INTR_ERRAGG0_MASK_MPU_CR5A0_AXIS_ADDR_ERR0 — Mask Error from MPU_ADDR_INTR to aggregated Error MPU_ADDR_INTR_ERRAGG1'b1 : Error is Masked1'b0 : Error is Unmasked
  [3] MPU_ADDR_INTR_ERRAGG0_MASK_MPU_L2_BANK_D_ADDR_ERR0 — Mask Error from MPU_ADDR_INTR to aggregated Error MPU_ADDR_INTR_ERRAGG1'b1 : Error is Masked1'b0 : Error is Unmasked
  [2] MPU_ADDR_INTR_ERRAGG0_MASK_MPU_L2_BANK_C_ADDR_ERR0 — Mask Error from MPU_ADDR_INTR to aggregated Error MPU_ADDR_INTR_ERRAGG1'b1 : Error is Masked1'b0 : Error is Unmasked
  [1] MPU_ADDR_INTR_ERRAGG0_MASK_MPU_L2_BANK_B_ADDR_ERR0 — Mask Error from MPU_ADDR_INTR to aggregated Error MPU_ADDR_INTR_ERRAGG1'b1 : Error is Masked1'b0 : Error is Unmasked
  [0] MPU_ADDR_INTR_ERRAGG0_MASK_MPU_L2_BANK_A_ADDR_ERR0 — Mask Error from MPU_ADDR_INTR to aggregated Error MPU_ADDR_INTR_ERRAGG1'b1 : Error is Masked1'b0 : Error is Unmasked
0x4024 MSS_CTRL_MPU_ADDR_INTR_ERRAGG0_STATUS rw — This register shows the Status of Unmasked MPU Address Errors to R5SS0 Core0 .
  [17] MPU_ADDR_INTR_ERRAGG0_STATUS_MPU_HSM_ADDR_ERR0 — Status of Error from MPU_ADDR_INTR. Set only if Interupt is unmasked in MPU_ADDR_INTR_ERRAGG_MASKWrie 0x1 to clear this Error.
  [16] MPU_ADDR_INTR_ERRAGG0_STATUS_MPU_CR5B1_AHB_ADDR_ERR0 — Status of Error from MPU_ADDR_INTR. Set only if Interupt is unmasked in MPU_ADDR_INTR_ERRAGG_MASKWrie 0x1 to clear this Error.
  [15] MPU_ADDR_INTR_ERRAGG0_STATUS_MPU_CR5A1_AHB_ADDR_ERR0 — Status of Error from MPU_ADDR_INTR. Set only if Interupt is unmasked in MPU_ADDR_INTR_ERRAGG_MASKWrie 0x1 to clear this Error.
  [14] MPU_ADDR_INTR_ERRAGG0_STATUS_MPU_CR5B0_AHB_ADDR_ERR0 — Status of Error from MPU_ADDR_INTR. Set only if Interupt is unmasked in MPU_ADDR_INTR_ERRAGG_MASKWrie 0x1 to clear this Error.
  [13] MPU_ADDR_INTR_ERRAGG0_STATUS_MPU_CR5A0_AHB_ADDR_ERR0 — Status of Error from MPU_ADDR_INTR. Set only if Interupt is unmasked in MPU_ADDR_INTR_ERRAGG_MASKWrie 0x1 to clear this Error.
  [12] MPU_ADDR_INTR_ERRAGG0_STATUS_MPU_SCRM2SCRP1_ADDR_ERR0 — Status of Error from MPU_ADDR_INTR. Set only if Interupt is unmasked in MPU_ADDR_INTR_ERRAGG_MASKWrie 0x1 to clear this Error.
  [11] MPU_ADDR_INTR_ERRAGG0_STATUS_MPU_SCRM2SCRP0_ADDR_ERR0 — Status of Error from MPU_ADDR_INTR. Set only if Interupt is unmasked in MPU_ADDR_INTR_ERRAGG_MASKWrie 0x1 to clear this Error.
  [10] MPU_ADDR_INTR_ERRAGG0_STATUS_MPU_QSPI_ADDR_ERR0 — Status of Error from MPU_ADDR_INTR. Set only if Interupt is unmasked in MPU_ADDR_INTR_ERRAGG_MASKWrie 0x1 to clear this Error.
  [9] MPU_ADDR_INTR_ERRAGG0_STATUS_MPU_MBOX_ADDR_ERR0 — Status of Error from MPU_ADDR_INTR. Set only if Interupt is unmasked in MPU_ADDR_INTR_ERRAGG_MASKWrie 0x1 to clear this Error.
  [8] MPU_ADDR_INTR_ERRAGG0_STATUS_MPU_DTHE_A_ADDR_ERR0 — Status of Error from MPU_ADDR_INTR. Set only if Interupt is unmasked in MPU_ADDR_INTR_ERRAGG_MASKWrie 0x1 to clear this Error.
  [7] MPU_ADDR_INTR_ERRAGG0_STATUS_MPU_CR5B1_AXIS_ADDR_ERR0 — Status of Error from MPU_ADDR_INTR. Set only if Interupt is unmasked in MPU_ADDR_INTR_ERRAGG_MASKWrie 0x1 to clear this Error.
  [6] MPU_ADDR_INTR_ERRAGG0_STATUS_MPU_CR5A1_AXIS_ADDR_ERR0 — Status of Error from MPU_ADDR_INTR. Set only if Interupt is unmasked in MPU_ADDR_INTR_ERRAGG_MASKWrie 0x1 to clear this Error.
  [5] MPU_ADDR_INTR_ERRAGG0_STATUS_MPU_CR5B0_AXIS_ADDR_ERR0 — Status of Error from MPU_ADDR_INTR. Set only if Interupt is unmasked in MPU_ADDR_INTR_ERRAGG_MASKWrie 0x1 to clear this Error.
  [4] MPU_ADDR_INTR_ERRAGG0_STATUS_MPU_CR5A0_AXIS_ADDR_ERR0 — Status of Error from MPU_ADDR_INTR. Set only if Interupt is unmasked in MPU_ADDR_INTR_ERRAGG_MASKWrie 0x1 to clear this Error.
  [3] MPU_ADDR_INTR_ERRAGG0_STATUS_MPU_L2_BANK_D_ADDR_ERR0 — Status of Error from MPU_ADDR_INTR. Set only if Interupt is unmasked in MPU_ADDR_INTR_ERRAGG_MASKWrie 0x1 to clear this Error.
  [2] MPU_ADDR_INTR_ERRAGG0_STATUS_MPU_L2_BANK_C_ADDR_ERR0 — Status of Error from MPU_ADDR_INTR. Set only if Interupt is unmasked in MPU_ADDR_INTR_ERRAGG_MASKWrie 0x1 to clear this Error.
  [1] MPU_ADDR_INTR_ERRAGG0_STATUS_MPU_L2_BANK_B_ADDR_ERR0 — Status of Error from MPU_ADDR_INTR. Set only if Interupt is unmasked in MPU_ADDR_INTR_ERRAGG_MASKWrie 0x1 to clear this Error.
  [0] MPU_ADDR_INTR_ERRAGG0_STATUS_MPU_L2_BANK_A_ADDR_ERR0 — Status of Error from MPU_ADDR_INTR. Set only if Interupt is unmasked in MPU_ADDR_INTR_ERRAGG_MASKWrie 0x1 to clear this Error.
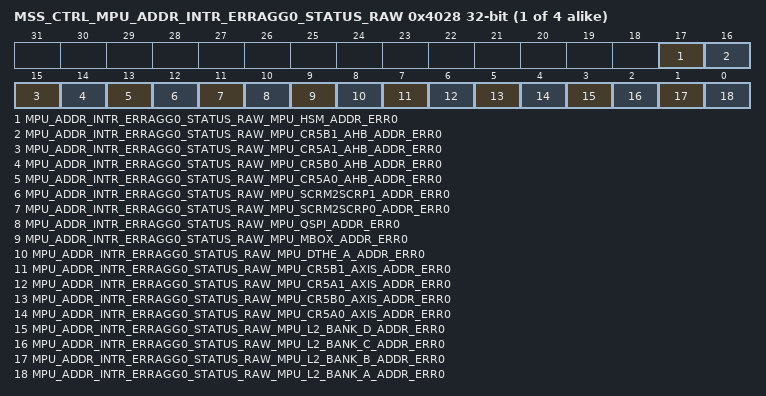
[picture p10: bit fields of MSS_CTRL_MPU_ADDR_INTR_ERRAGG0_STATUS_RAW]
{0x4028+0x4000*i} MSS_CTRL_MPU_ADDR_INTR_ERRAGG{i}_STATUS_RAW rw (i=0..3) — This register shows the Status of all MPU Address Errors.
  [17] MPU_ADDR_INTR_ERRAGG{i}_STATUS_RAW_MPU_HSM_ADDR_ERR{i} — Raw Status of Error from MPU_ADDR_INTR. Set irrespective if the Interupt is masked or unmasked in MPU_ADDR_INTR_ERRAGG_MASK
  [16] MPU_ADDR_INTR_ERRAGG{i}_STATUS_RAW_MPU_CR5B1_AHB_ADDR_ERR{i} — Raw Status of Error from MPU_ADDR_INTR. Set irrespective if the Interupt is masked or unmasked in MPU_ADDR_INTR_ERRAGG_MASK
  [15] MPU_ADDR_INTR_ERRAGG{i}_STATUS_RAW_MPU_CR5A1_AHB_ADDR_ERR{i} — Raw Status of Error from MPU_ADDR_INTR. Set irrespective if the Interupt is masked or unmasked in MPU_ADDR_INTR_ERRAGG_MASK
  [14] MPU_ADDR_INTR_ERRAGG{i}_STATUS_RAW_MPU_CR5B0_AHB_ADDR_ERR{i} — Raw Status of Error from MPU_ADDR_INTR. Set irrespective if the Interupt is masked or unmasked in MPU_ADDR_INTR_ERRAGG_MASK
  [13] MPU_ADDR_INTR_ERRAGG{i}_STATUS_RAW_MPU_CR5A0_AHB_ADDR_ERR{i} — Raw Status of Error from MPU_ADDR_INTR. Set irrespective if the Interupt is masked or unmasked in MPU_ADDR_INTR_ERRAGG_MASK
  [12] MPU_ADDR_INTR_ERRAGG{i}_STATUS_RAW_MPU_SCRM2SCRP1_ADDR_ERR{i} — Raw Status of Error from MPU_ADDR_INTR. Set irrespective if the Interupt is masked or unmasked in MPU_ADDR_INTR_ERRAGG_MASK
  [11] MPU_ADDR_INTR_ERRAGG{i}_STATUS_RAW_MPU_SCRM2SCRP0_ADDR_ERR{i} — Raw Status of Error from MPU_ADDR_INTR. Set irrespective if the Interupt is masked or unmasked in MPU_ADDR_INTR_ERRAGG_MASK
  [10] MPU_ADDR_INTR_ERRAGG{i}_STATUS_RAW_MPU_QSPI_ADDR_ERR{i} — Raw Status of Error from MPU_ADDR_INTR. Set irrespective if the Interupt is masked or unmasked in MPU_ADDR_INTR_ERRAGG_MASK
  [9] MPU_ADDR_INTR_ERRAGG{i}_STATUS_RAW_MPU_MBOX_ADDR_ERR{i} — Raw Status of Error from MPU_ADDR_INTR. Set irrespective if the Interupt is masked or unmasked in MPU_ADDR_INTR_ERRAGG_MASK
  [8] MPU_ADDR_INTR_ERRAGG{i}_STATUS_RAW_MPU_DTHE_A_ADDR_ERR{i} — Raw Status of Error from MPU_ADDR_INTR. Set irrespective if the Interupt is masked or unmasked in MPU_ADDR_INTR_ERRAGG_MASK
  [7] MPU_ADDR_INTR_ERRAGG{i}_STATUS_RAW_MPU_CR5B1_AXIS_ADDR_ERR{i} — Raw Status of Error from MPU_ADDR_INTR. Set irrespective if the Interupt is masked or unmasked in MPU_ADDR_INTR_ERRAGG_MASK
  [6] MPU_ADDR_INTR_ERRAGG{i}_STATUS_RAW_MPU_CR5A1_AXIS_ADDR_ERR{i} — Raw Status of Error from MPU_ADDR_INTR. Set irrespective if the Interupt is masked or unmasked in MPU_ADDR_INTR_ERRAGG_MASK
  [5] MPU_ADDR_INTR_ERRAGG{i}_STATUS_RAW_MPU_CR5B0_AXIS_ADDR_ERR{i} — Raw Status of Error from MPU_ADDR_INTR. Set irrespective if the Interupt is masked or unmasked in MPU_ADDR_INTR_ERRAGG_MASK
  [4] MPU_ADDR_INTR_ERRAGG{i}_STATUS_RAW_MPU_CR5A0_AXIS_ADDR_ERR{i} — Raw Status of Error from MPU_ADDR_INTR. Set irrespective if the Interupt is masked or unmasked in MPU_ADDR_INTR_ERRAGG_MASK
  [3] MPU_ADDR_INTR_ERRAGG{i}_STATUS_RAW_MPU_L2_BANK_D_ADDR_ERR{i} — Raw Status of Error from MPU_ADDR_INTR. Set irrespective if the Interupt is masked or unmasked in MPU_ADDR_INTR_ERRAGG_MASK
  [2] MPU_ADDR_INTR_ERRAGG{i}_STATUS_RAW_MPU_L2_BANK_C_ADDR_ERR{i} — Raw Status of Error from MPU_ADDR_INTR. Set irrespective if the Interupt is masked or unmasked in MPU_ADDR_INTR_ERRAGG_MASK
  [1] MPU_ADDR_INTR_ERRAGG{i}_STATUS_RAW_MPU_L2_BANK_B_ADDR_ERR{i} — Raw Status of Error from MPU_ADDR_INTR. Set irrespective if the Interupt is masked or unmasked in MPU_ADDR_INTR_ERRAGG_MASK
  [0] MPU_ADDR_INTR_ERRAGG{i}_STATUS_RAW_MPU_L2_BANK_A_ADDR_ERR{i} — Raw Status of Error from MPU_ADDR_INTR. Set irrespective if the Interupt is masked or unmasked in MPU_ADDR_INTR_ERRAGG_MASK
